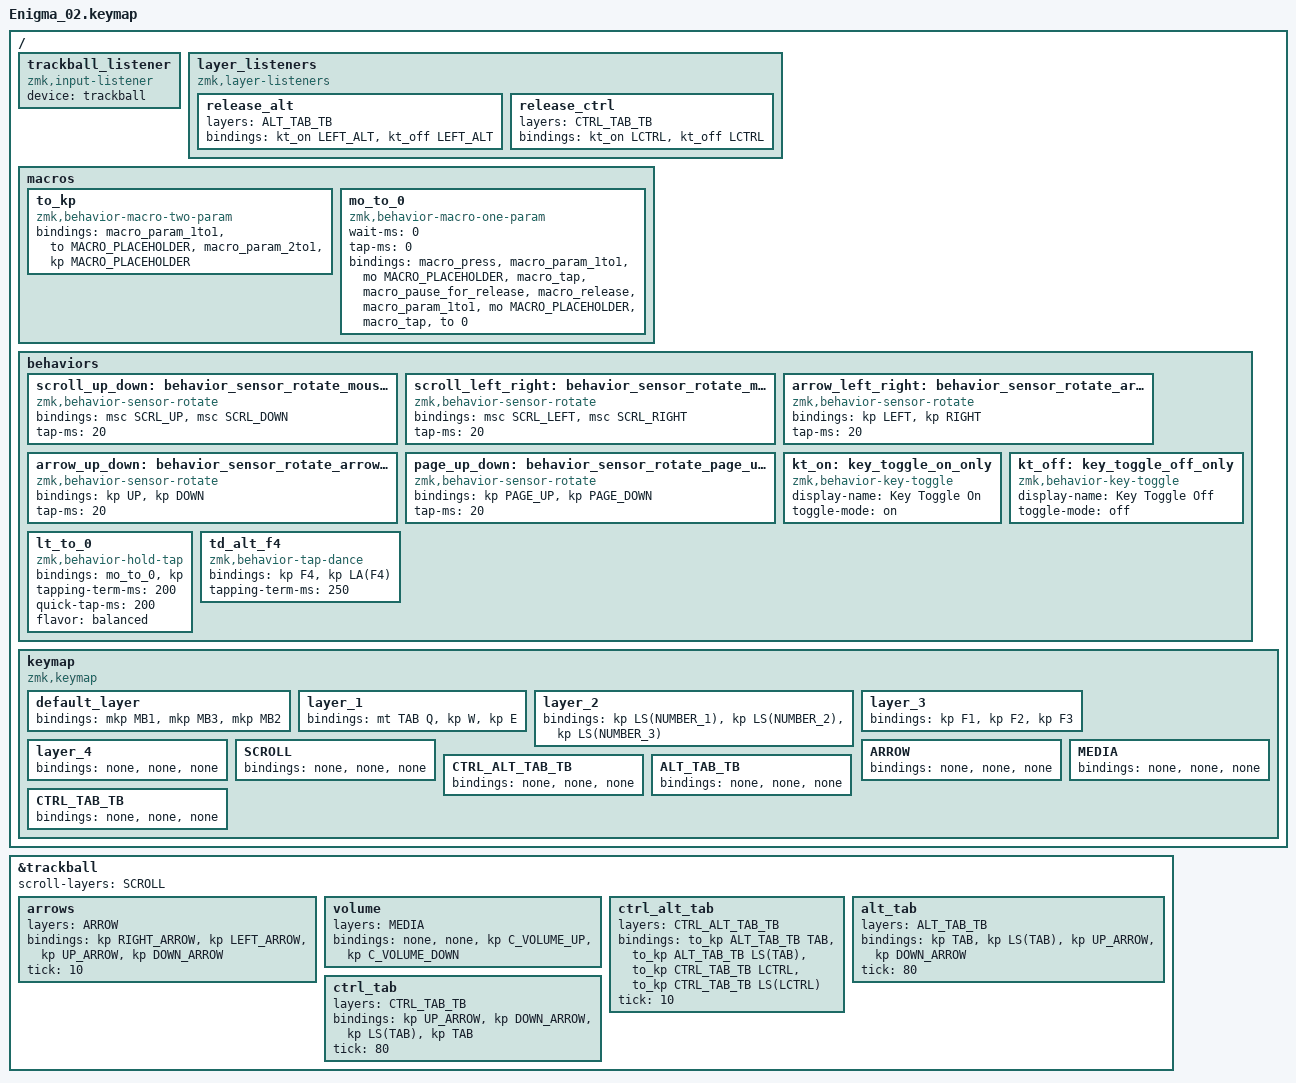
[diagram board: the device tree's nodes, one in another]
#include <behaviors.dtsi>
#include <dt-bindings/zmk/bt.h>
#include <dt-bindings/zmk/keys.h>
#include <dt-bindings/zmk/outputs.h>
#include <dt-bindings/zmk/pointing.h>

#define ZMK_POINTING_DEFAULT_SCRL_VAL 100

#define SCROLL 5
#define ARROW 6
#define MEDIA 7
#define CTRL_ALT_TAB_TB 8
#define ALT_TAB_TB 9
#define CTRL_TAB_TB 10


/ {
    trackball_listener {
        compatible = "zmk,input-listener";
        device = <&trackball>;
    };

    layer_listeners {
        compatible = "zmk,layer-listeners";

        release_alt {
            layers = <ALT_TAB_TB>;
            bindings = <&kt_on LEFT_ALT &kt_off LEFT_ALT>;
        };

        release_ctrl {
            layers = <CTRL_TAB_TB>;
            bindings = <&kt_on LCTRL &kt_off LCTRL>;
        };
    };

    macros {
        to_kp: to_kp {
            compatible = "zmk,behavior-macro-two-param";
            #binding-cells = <2>;
            bindings = <&macro_param_1to1 &to MACRO_PLACEHOLDER &macro_param_2to1 &kp MACRO_PLACEHOLDER>;
        };

        mo_to_0: mo_to_0 {
            compatible = "zmk,behavior-macro-one-param";
            wait-ms = <0>;
            tap-ms = <0>;
            #binding-cells = <1>;
            bindings =
                <&macro_press>,
                <&macro_param_1to1 &mo MACRO_PLACEHOLDER>,
                <&macro_tap>,
                <&macro_pause_for_release>,
                <&macro_release>,
                <&macro_param_1to1 &mo MACRO_PLACEHOLDER>,
                <&macro_tap>,
                <&to 0>;
        };
    };

    behaviors {
        scroll_up_down: behavior_sensor_rotate_mouse_wheel_up_down {
            compatible = "zmk,behavior-sensor-rotate";
            #sensor-binding-cells = <0>;
            bindings = <&msc SCRL_UP>, <&msc SCRL_DOWN>;

            tap-ms = <20>;
        };

        scroll_left_right: behavior_sensor_rotate_mouse_wheel_left_right {
            compatible = "zmk,behavior-sensor-rotate";
            #sensor-binding-cells = <0>;
            bindings = <&msc SCRL_LEFT>, <&msc SCRL_RIGHT>;

            tap-ms = <20>;
        };

        arrow_left_right: behavior_sensor_rotate_arrow_le {
            compatible = "zmk,behavior-sensor-rotate";
            #sensor-binding-cells = <0>;
            bindings = <&kp LEFT>, <&kp RIGHT>;

            tap-ms = <20>;
        };

        arrow_up_down: behavior_sensor_rotate_arrow_up {
            compatible = "zmk,behavior-sensor-rotate";
            #sensor-binding-cells = <0>;
            bindings = <&kp UP>, <&kp DOWN>;

            tap-ms = <20>;
        };

        page_up_down: behavior_sensor_rotate_page_up_ {
            compatible = "zmk,behavior-sensor-rotate";
            #sensor-binding-cells = <0>;
            bindings = <&kp PAGE_UP>, <&kp PAGE_DOWN>;

            tap-ms = <20>;
        };
        kt_on: key_toggle_on_only {
            compatible = "zmk,behavior-key-toggle";
            #binding-cells = <1>;
            display-name = "Key Toggle On";
            toggle-mode = "on";
        };

        kt_off: key_toggle_off_only {
            compatible = "zmk,behavior-key-toggle";
            #binding-cells = <1>;
            display-name = "Key Toggle Off";
            toggle-mode = "off";
        };

        lt_to_0: lt_to_0 {
            compatible = "zmk,behavior-hold-tap";
            bindings = <&mo_to_0>, <&kp>;
            #binding-cells = <2>;
            tapping-term-ms = <200>;
            quick-tap-ms = <200>;
            flavor = "balanced";
        };

        td_alt_f4: td_alt_f4 {
            compatible = "zmk,behavior-tap-dance";
            #binding-cells = <0>;
            bindings = <&kp F4>, <&kp LA(F4)>;

            tapping-term-ms = <250>;
        };
    };

    keymap {
        compatible = "zmk,keymap";

        default_layer {
            bindings = <
&mkp MB1  &mkp MB3  &mkp MB2
            >;
        };

        layer_1 {
            bindings = <
&mt TAB Q  &kp W   &kp E 
            >;
        };

        layer_2 {
            bindings = <
&kp LS(NUMBER_1)  &kp LS(NUMBER_2)  &kp LS(NUMBER_3)
            >;
        };

        layer_3 {
            bindings = <
&kp F1   &kp F2   &kp F3
            >;
        };

        layer_4 {
            bindings = <
&none   &none   &none
            >;
        };

        SCROLL {
            bindings = <
&none   &none   &none
            >;
        };

        ARROW {
            bindings = <
&none   &none   &none
            >;
        };

        MEDIA {
            bindings = <
&none   &none   &none
            >;
        };

        CTRL_ALT_TAB_TB {
            bindings = <
&none   &none   &none
            >;
        };

        ALT_TAB_TB {
            bindings = <
&none   &none   &none
            >;
        };

        CTRL_TAB_TB {
            bindings = <
&none   &none   &none
            >;
        };
    };
};


&trackball {
    scroll-layers = <SCROLL>;
    // snipe-layers = <3>;

    arrows {
        layers = <ARROW>;
        bindings =
            <&kp RIGHT_ARROW>,
            <&kp LEFT_ARROW>,
            <&kp UP_ARROW>,
            <&kp DOWN_ARROW>;

        tick = <10>;
    };

     volume {
         layers = <MEDIA>;
         bindings =
             <&none>,
             <&none>,
             <&kp C_VOLUME_UP>,
             <&kp C_VOLUME_DOWN>;
    };

    ctrl_alt_tab {
        layers = <CTRL_ALT_TAB_TB>;
        bindings =
            <&to_kp ALT_TAB_TB TAB>,
            <&to_kp ALT_TAB_TB LS(TAB)>,
            <&to_kp CTRL_TAB_TB LCTRL>,
            <&to_kp CTRL_TAB_TB LS(LCTRL)>;

        tick = <10>;
    };

    alt_tab {
        layers = <ALT_TAB_TB >;
        bindings =
            <&kp TAB>,
            <&kp LS(TAB)>,
            <&kp UP_ARROW>,
            <&kp DOWN_ARROW>;

        tick = <80>;
    };

    ctrl_tab {
        layers = <CTRL_TAB_TB>;
        bindings =
            <&kp UP_ARROW>,
            <&kp DOWN_ARROW>,
            <&kp LS(TAB)>,
            <&kp TAB>;

        tick = <80>;
    };
};
